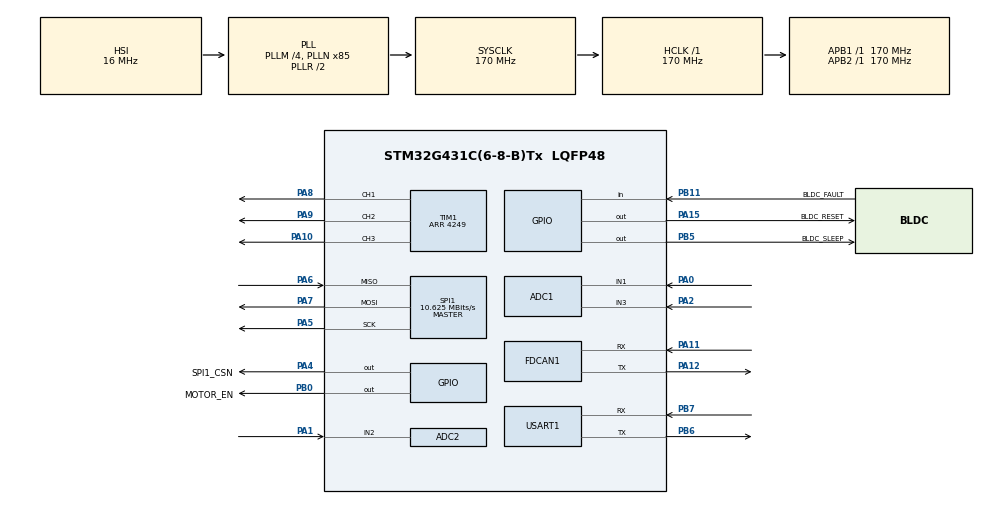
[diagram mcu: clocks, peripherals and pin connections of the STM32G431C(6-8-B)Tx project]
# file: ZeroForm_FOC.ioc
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ADC1.Channel-0\#ChannelRegularConversion=ADC_CHANNEL_3
ADC1.Channel-1\#ChannelRegularConversion=ADC_CHANNEL_TEMPSENSOR_ADC1
ADC1.ContinuousConvMode=DISABLE
ADC1.EnableInjectedConversion=ENABLE
ADC1.ExternalTrigInjecConv=ADC_EXTERNALTRIGINJEC_T1_TRGO
ADC1.InjNumberOfConversion=1
ADC1.InjectedChannel-2\#ChannelInjectedConversion=ADC_CHANNEL_1
ADC1.InjectedOffsetNumber-2\#ChannelInjectedConversion=ADC_OFFSET_NONE
ADC1.InjectedRank-2\#ChannelInjectedConversion=1
ADC1.InjectedSamplingTime-2\#ChannelInjectedConversion=ADC_SAMPLETIME_12CYCLES_5
ADC1.Mode=ADC_DUALMODE_REGSIMULT_INJECSIMULT
ADC1.NbrOfConversion=2
ADC1.NbrOfConversionFlag=1
ADC1.OffsetNumber-0\#ChannelRegularConversion=ADC_OFFSET_NONE
ADC1.OffsetNumber-1\#ChannelRegularConversion=ADC_OFFSET_NONE
ADC1.Overrun=ADC_OVR_DATA_OVERWRITTEN
ADC1.Rank-0\#ChannelRegularConversion=1
ADC1.Rank-1\#ChannelRegularConversion=2
ADC1.Rank1_Channel=ADC_CHANNEL_1
ADC1.SamplingTime-0\#ChannelRegularConversion=ADC_SAMPLETIME_640CYCLES_5
ADC1.SamplingTime-1\#ChannelRegularConversion=ADC_SAMPLETIME_640CYCLES_5
ADC1.master=1
ADC2.EnableInjectedConversion=ENABLE
ADC2.EnableRegularConversion=DISABLE
ADC2.InjNumberOfConversion=1
ADC2.InjectedChannel-1\#ChannelInjectedConversion=ADC_CHANNEL_2
ADC2.InjectedOffsetNumber-1\#ChannelInjectedConversion=ADC_OFFSET_NONE
ADC2.InjectedRank-1\#ChannelInjectedConversion=1
ADC2.InjectedSamplingTime-1\#ChannelInjectedConversion=ADC_SAMPLETIME_12CYCLES_5
ADC2.Mode=ADC_DUALMODE_REGSIMULT_INJECSIMULT
ADC2.Overrun=ADC_OVR_DATA_OVERWRITTEN
ADC2.Rank1_Channel=ADC_CHANNEL_2
FDCAN1.CalculateBaudRateNominal=999999
FDCAN1.CalculateTimeBitNominal=1000
FDCAN1.CalculateTimeQuantumNominal=29.411764705882355
FDCAN1.DataSyncJumpWidth=4
FDCAN1.DataTimeSeg1=26
FDCAN1.FrameFormat=FDCAN_FRAME_FD_BRS
FDCAN1.NominalPrescaler=5
FDCAN1.NominalSyncJumpWidth=4
FDCAN1.NominalTimeSeg1=26
FDCAN1.NominalTimeSeg2=7
Mcu.Family=STM32G4
Mcu.Name=STM32G431C(6-8-B)Tx
Mcu.Package=LQFP48
NVIC.ADC1_2_IRQn=true\:1\:0\:true\:false\:true\:true\:true\:true
NVIC.FDCAN1_IT0_IRQn=true\:0\:0\:false\:false\:true\:true\:true\:true
NVIC.PriorityGroup=NVIC_PRIORITYGROUP_4
NVIC.USART1_IRQn=true\:0\:0\:false\:false\:true\:true\:true\:true
PA0.Mode=IN1-Single-Ended
PA0.Signal=ADC1_IN1
PA1.Mode=IN2-Single-Ended
PA1.Signal=ADC2_IN2
PA10.Signal=S_TIM1_CH3
PA11.Mode=FDCAN_Activate
PA11.Signal=FDCAN1_RX
PA12.Mode=FDCAN_Activate
PA12.Signal=FDCAN1_TX
PA13.Mode=Serial_Wire
PA13.Signal=SYS_JTMS-SWDIO
PA14.Mode=Serial_Wire
PA14.Signal=SYS_JTCK-SWCLK
PA15.GPIO_Label=BLDC_RESET
PA15.Signal=GPIO_Output
PA2.Mode=IN3-Single-Ended
PA2.Signal=ADC1_IN3
PA4.GPIO_Label=SPI1_CSN
PA4.Signal=GPIO_Output
PA5.Mode=Full_Duplex_Master
PA5.Signal=SPI1_SCK
PA6.Mode=Full_Duplex_Master
PA6.Signal=SPI1_MISO
PA7.Mode=Full_Duplex_Master
PA7.Signal=SPI1_MOSI
PA8.Signal=S_TIM1_CH1
PA9.Signal=S_TIM1_CH2
PB0.GPIO_Label=MOTOR_EN
PB0.Signal=GPIO_Output
PB11.GPIO_Label=BLDC_FAULT
PB11.Signal=GPIO_Input
PB5.GPIO_Label=BLDC_SLEEP
PB5.Signal=GPIO_Output
PB6.Mode=Asynchronous
PB6.Signal=USART1_TX
PB7.Mode=Asynchronous
PB7.Signal=USART1_RX
PF0-OSC_IN.Mode=HSE-External-Oscillator
PF0-OSC_IN.Signal=RCC_OSC_IN
PF1-OSC_OUT.Mode=HSE-External-Oscillator
PF1-OSC_OUT.Signal=RCC_OSC_OUT
ProjectManager.HeapSize=0x200
ProjectManager.StackSize=0x400
ProjectManager.TargetToolchain=CMake
RCC.ADC12Freq_Value=170000000
RCC.AHBFreq_Value=170000000
RCC.APB1Freq_Value=170000000
RCC.APB1TimFreq_Value=170000000
RCC.APB2Freq_Value=170000000
RCC.APB2TimFreq_Value=170000000
RCC.CortexFreq_Value=170000000
RCC.EXTERNAL_CLOCK_VALUE=12288000
RCC.HCLKFreq_Value=170000000
RCC.HSE_VALUE=8000000
RCC.HSI48_VALUE=48000000
RCC.HSI_VALUE=16000000
RCC.LSE_VALUE=32768
RCC.PLLM=RCC_PLLM_DIV4
RCC.PLLN=85
RCC.SYSCLKFreq_VALUE=170000000
RCC.SYSCLKSource=RCC_SYSCLKSOURCE_PLLCLK
RCC.USBFreq_Value=170000000
RCC.VCOOutputFreq_Value=340000000
SH.S_TIM1_CH1.0=TIM1_CH1,PWM Generation1 CH1
SH.S_TIM1_CH2.0=TIM1_CH2,PWM Generation2 CH2
SH.S_TIM1_CH3.0=TIM1_CH3,PWM Generation3 CH3
SPI1.BaudRatePrescaler=SPI_BAUDRATEPRESCALER_16
SPI1.CLKPhase=SPI_PHASE_2EDGE
SPI1.CLKPolarity=SPI_POLARITY_HIGH
SPI1.CalculateBaudRate=10.625 MBits/s
SPI1.DataSize=SPI_DATASIZE_8BIT
SPI1.Direction=SPI_DIRECTION_2LINES
SPI1.Mode=SPI_MODE_MASTER
SPI1.VirtualType=VM_MASTER
TIM1.Channel-PWM\ Generation1\ CH1=TIM_CHANNEL_1
TIM1.Channel-PWM\ Generation2\ CH2=TIM_CHANNEL_2
TIM1.Channel-PWM\ Generation3\ CH3=TIM_CHANNEL_3
TIM1.CounterMode=TIM_COUNTERMODE_CENTERALIGNED1
TIM1.PeriodNoDither=4249
TIM1.RepetitionCounter=1
TIM1.TIM_MasterOutputTrigger=TIM_TRGO_UPDATE
USART1.VirtualMode-Asynchronous=VM_ASYNC
VP_ADC1_TempSens_Input.Mode=IN-TempSens
VP_CORDIC_VS_CORDIC.Mode=CORDIC_Activate
VP_CRC_VS_CRC.Mode=CRC_Activate
VP_SYS_VS_DBSignals.Mode=DisableDeadBatterySignals
board=custom

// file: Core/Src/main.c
/* USER CODE BEGIN Header */
/**
  ******************************************************************************
  * @file           : main.c
  * @brief          : Main program body
  ******************************************************************************
  * @attention
  *
  * Copyright (c) 2026 STMicroelectronics.
  * All rights reserved.
  *
  * This software is licensed under terms that can be found in the LICENSE file
  * in the root directory of this software component.
  * If no LICENSE file comes with this software, it is provided AS-IS.
  *
  ******************************************************************************
  */
/* USER CODE END Header */
#include "main.h"

/* USER CODE BEGIN Includes */
#include "app_main.h"
#include "stdio.h"
/* USER CODE END Includes */

ADC_HandleTypeDef hadc1;
ADC_HandleTypeDef hadc2;

CORDIC_HandleTypeDef hcordic;

CRC_HandleTypeDef hcrc;

FDCAN_HandleTypeDef hfdcan1;

SPI_HandleTypeDef hspi1;

TIM_HandleTypeDef htim1;

UART_HandleTypeDef huart1;

void SystemClock_Config(void);
static void MX_GPIO_Init(void);
static void MX_ADC1_Init(void);
static void MX_ADC2_Init(void);
static void MX_CORDIC_Init(void);
static void MX_CRC_Init(void);
static void MX_FDCAN1_Init(void);
static void MX_SPI1_Init(void);
static void MX_TIM1_Init(void);
static void MX_USART1_UART_Init(void);

int main(void)
{

  /* MCU Configuration--------------------------------------------------------*/

  /* Reset of all peripherals, Initializes the Flash interface and the Systick. */
  HAL_Init();

  /* Configure the system clock */
  SystemClock_Config();

  /* Initialize all configured peripherals */
  MX_GPIO_Init();
  MX_ADC1_Init();
  MX_ADC2_Init();
  MX_CORDIC_Init();
  MX_CRC_Init();
  MX_FDCAN1_Init();
  MX_SPI1_Init();
  MX_TIM1_Init();
  MX_USART1_UART_Init();
  /* USER CODE BEGIN 2 */
    App_Init();

  /* USER CODE END 2 */

  /* Infinite loop */
    while (1) {

    }
}

void SystemClock_Config(void)
{
  RCC_OscInitTypeDef RCC_OscInitStruct = {0};
  RCC_ClkInitTypeDef RCC_ClkInitStruct = {0};

  /** Configure the main internal regulator output voltage
  */
  HAL_PWREx_ControlVoltageScaling(PWR_REGULATOR_VOLTAGE_SCALE1_BOOST);

  /** Initializes the RCC Oscillators according to the specified parameters
  * in the RCC_OscInitTypeDef structure.
  */
  RCC_OscInitStruct.OscillatorType = RCC_OSCILLATORTYPE_HSI;
  RCC_OscInitStruct.HSIState = RCC_HSI_ON;
  RCC_OscInitStruct.HSICalibrationValue = RCC_HSICALIBRATION_DEFAULT;
  RCC_OscInitStruct.PLL.PLLState = RCC_PLL_ON;
  RCC_OscInitStruct.PLL.PLLSource = RCC_PLLSOURCE_HSI;
  RCC_OscInitStruct.PLL.PLLM = RCC_PLLM_DIV4;
  RCC_OscInitStruct.PLL.PLLN = 85;
  RCC_OscInitStruct.PLL.PLLP = RCC_PLLP_DIV2;
  RCC_OscInitStruct.PLL.PLLQ = RCC_PLLQ_DIV2;
  RCC_OscInitStruct.PLL.PLLR = RCC_PLLR_DIV2;
  if (HAL_RCC_OscConfig(&RCC_OscInitStruct) != HAL_OK)
  {
    Error_Handler();
  }

  /** Initializes the CPU, AHB and APB buses clocks
  */
  RCC_ClkInitStruct.ClockType = RCC_CLOCKTYPE_HCLK|RCC_CLOCKTYPE_SYSCLK
                              |RCC_CLOCKTYPE_PCLK1|RCC_CLOCKTYPE_PCLK2;
  RCC_ClkInitStruct.SYSCLKSource = RCC_SYSCLKSOURCE_PLLCLK;
  RCC_ClkInitStruct.AHBCLKDivider = RCC_SYSCLK_DIV1;
  RCC_ClkInitStruct.APB1CLKDivider = RCC_HCLK_DIV1;
  RCC_ClkInitStruct.APB2CLKDivider = RCC_HCLK_DIV1;

  if (HAL_RCC_ClockConfig(&RCC_ClkInitStruct, FLASH_LATENCY_4) != HAL_OK)
  {
    Error_Handler();
  }
}

static void MX_ADC1_Init(void)
{

  ADC_MultiModeTypeDef multimode = {0};
  ADC_ChannelConfTypeDef sConfig = {0};
  ADC_InjectionConfTypeDef sConfigInjected = {0};

  /** Common config
  */
  hadc1.Instance = ADC1;
  hadc1.Init.ClockPrescaler = ADC_CLOCK_SYNC_PCLK_DIV4;
  hadc1.Init.Resolution = ADC_RESOLUTION_12B;
  hadc1.Init.DataAlign = ADC_DATAALIGN_RIGHT;
  hadc1.Init.GainCompensation = 0;
  hadc1.Init.ScanConvMode = ADC_SCAN_ENABLE;
  hadc1.Init.EOCSelection = ADC_EOC_SINGLE_CONV;
  hadc1.Init.LowPowerAutoWait = DISABLE;
  hadc1.Init.ContinuousConvMode = DISABLE;
  hadc1.Init.NbrOfConversion = 2;
  hadc1.Init.DiscontinuousConvMode = DISABLE;
  hadc1.Init.ExternalTrigConv = ADC_SOFTWARE_START;
  hadc1.Init.ExternalTrigConvEdge = ADC_EXTERNALTRIGCONVEDGE_NONE;
  hadc1.Init.DMAContinuousRequests = DISABLE;
  hadc1.Init.Overrun = ADC_OVR_DATA_OVERWRITTEN;
  hadc1.Init.OversamplingMode = DISABLE;
  if (HAL_ADC_Init(&hadc1) != HAL_OK)
  {
    Error_Handler();
  }

  /** Configure the ADC multi-mode
  */
  multimode.Mode = ADC_DUALMODE_REGSIMULT_INJECSIMULT;
  multimode.DMAAccessMode = ADC_DMAACCESSMODE_DISABLED;
  multimode.TwoSamplingDelay = ADC_TWOSAMPLINGDELAY_1CYCLE;
  if (HAL_ADCEx_MultiModeConfigChannel(&hadc1, &multimode) != HAL_OK)
  {
    Error_Handler();
  }

  /** Configure Regular Channel
  */
  sConfig.Channel = ADC_CHANNEL_3;
  sConfig.Rank = ADC_REGULAR_RANK_1;
  sConfig.SamplingTime = ADC_SAMPLETIME_640CYCLES_5;
  sConfig.SingleDiff = ADC_SINGLE_ENDED;
  sConfig.OffsetNumber = ADC_OFFSET_NONE;
  sConfig.Offset = 0;
  if (HAL_ADC_ConfigChannel(&hadc1, &sConfig) != HAL_OK)
  {
    Error_Handler();
  }

  /** Configure Regular Channel
  */
  sConfig.Channel = ADC_CHANNEL_TEMPSENSOR_ADC1;
  sConfig.Rank = ADC_REGULAR_RANK_2;
  if (HAL_ADC_ConfigChannel(&hadc1, &sConfig) != HAL_OK)
  {
    Error_Handler();
  }

  /** Configure Injected Channel
  */
  sConfigInjected.InjectedChannel = ADC_CHANNEL_1;
  sConfigInjected.InjectedRank = ADC_INJECTED_RANK_1;
  sConfigInjected.InjectedSamplingTime = ADC_SAMPLETIME_12CYCLES_5;
  sConfigInjected.InjectedSingleDiff = ADC_SINGLE_ENDED;
  sConfigInjected.InjectedOffsetNumber = ADC_OFFSET_NONE;
  sConfigInjected.InjectedOffset = 0;
  sConfigInjected.InjectedNbrOfConversion = 1;
  sConfigInjected.InjectedDiscontinuousConvMode = DISABLE;
  sConfigInjected.AutoInjectedConv = DISABLE;
  sConfigInjected.QueueInjectedContext = DISABLE;
  sConfigInjected.ExternalTrigInjecConv = ADC_EXTERNALTRIGINJEC_T1_TRGO;
  sConfigInjected.ExternalTrigInjecConvEdge = ADC_EXTERNALTRIGINJECCONV_EDGE_RISING;
  sConfigInjected.InjecOversamplingMode = DISABLE;
  if (HAL_ADCEx_InjectedConfigChannel(&hadc1, &sConfigInjected) != HAL_OK)
  {
    Error_Handler();
  }

}

static void MX_ADC2_Init(void)
{

  ADC_InjectionConfTypeDef sConfigInjected = {0};

  /** Common config
  */
  hadc2.Instance = ADC2;
  hadc2.Init.ClockPrescaler = ADC_CLOCK_SYNC_PCLK_DIV4;
  hadc2.Init.Resolution = ADC_RESOLUTION_12B;
  hadc2.Init.DataAlign = ADC_DATAALIGN_RIGHT;
  hadc2.Init.GainCompensation = 0;
  hadc2.Init.ScanConvMode = ADC_SCAN_DISABLE;
  hadc2.Init.EOCSelection = ADC_EOC_SINGLE_CONV;
  hadc2.Init.LowPowerAutoWait = DISABLE;
  hadc2.Init.ContinuousConvMode = DISABLE;
  hadc2.Init.NbrOfConversion = 1;
  hadc2.Init.DiscontinuousConvMode = DISABLE;
  hadc2.Init.DMAContinuousRequests = DISABLE;
  hadc2.Init.Overrun = ADC_OVR_DATA_OVERWRITTEN;
  hadc2.Init.OversamplingMode = DISABLE;
  if (HAL_ADC_Init(&hadc2) != HAL_OK)
  {
    Error_Handler();
  }

  /** Configure Injected Channel
  */
  sConfigInjected.InjectedChannel = ADC_CHANNEL_2;
  sConfigInjected.InjectedRank = ADC_INJECTED_RANK_1;
  sConfigInjected.InjectedSamplingTime = ADC_SAMPLETIME_12CYCLES_5;
  sConfigInjected.InjectedSingleDiff = ADC_SINGLE_ENDED;
  sConfigInjected.InjectedOffsetNumber = ADC_OFFSET_NONE;
  sConfigInjected.InjectedOffset = 0;
  sConfigInjected.InjectedNbrOfConversion = 1;
  sConfigInjected.InjectedDiscontinuousConvMode = DISABLE;
  sConfigInjected.AutoInjectedConv = DISABLE;
  sConfigInjected.QueueInjectedContext = DISABLE;
  sConfigInjected.InjecOversamplingMode = DISABLE;
  if (HAL_ADCEx_InjectedConfigChannel(&hadc2, &sConfigInjected) != HAL_OK)
  {
    Error_Handler();
  }

}

static void MX_CORDIC_Init(void)
{

  hcordic.Instance = CORDIC;
  if (HAL_CORDIC_Init(&hcordic) != HAL_OK)
  {
    Error_Handler();
  }

}

static void MX_CRC_Init(void)
{

  hcrc.Instance = CRC;
  hcrc.Init.DefaultPolynomialUse = DEFAULT_POLYNOMIAL_ENABLE;
  hcrc.Init.DefaultInitValueUse = DEFAULT_INIT_VALUE_ENABLE;
  hcrc.Init.InputDataInversionMode = CRC_INPUTDATA_INVERSION_NONE;
  hcrc.Init.OutputDataInversionMode = CRC_OUTPUTDATA_INVERSION_DISABLE;
  hcrc.InputDataFormat = CRC_INPUTDATA_FORMAT_BYTES;
  if (HAL_CRC_Init(&hcrc) != HAL_OK)
  {
    Error_Handler();
  }

}

static void MX_FDCAN1_Init(void)
{

  hfdcan1.Instance = FDCAN1;
  hfdcan1.Init.ClockDivider = FDCAN_CLOCK_DIV1;
  hfdcan1.Init.FrameFormat = FDCAN_FRAME_FD_BRS;
  hfdcan1.Init.Mode = FDCAN_MODE_NORMAL;
  hfdcan1.Init.AutoRetransmission = DISABLE;
  hfdcan1.Init.TransmitPause = DISABLE;
  hfdcan1.Init.ProtocolException = DISABLE;
  hfdcan1.Init.NominalPrescaler = 5;
  hfdcan1.Init.NominalSyncJumpWidth = 4;
  hfdcan1.Init.NominalTimeSeg1 = 26;
  hfdcan1.Init.NominalTimeSeg2 = 7;
  hfdcan1.Init.DataPrescaler = 1;
  hfdcan1.Init.DataSyncJumpWidth = 4;
  hfdcan1.Init.DataTimeSeg1 = 26;
  hfdcan1.Init.DataTimeSeg2 = 1;
  hfdcan1.Init.StdFiltersNbr = 0;
  hfdcan1.Init.ExtFiltersNbr = 0;
  hfdcan1.Init.TxFifoQueueMode = FDCAN_TX_FIFO_OPERATION;
  if (HAL_FDCAN_Init(&hfdcan1) != HAL_OK)
  {
    Error_Handler();
  }

}

static void MX_SPI1_Init(void)
{

  /* SPI1 parameter configuration*/
  hspi1.Instance = SPI1;
  hspi1.Init.Mode = SPI_MODE_MASTER;
  hspi1.Init.Direction = SPI_DIRECTION_2LINES;
  hspi1.Init.DataSize = SPI_DATASIZE_8BIT;
  hspi1.Init.CLKPolarity = SPI_POLARITY_HIGH;
  hspi1.Init.CLKPhase = SPI_PHASE_2EDGE;
  hspi1.Init.NSS = SPI_NSS_SOFT;
  hspi1.Init.BaudRatePrescaler = SPI_BAUDRATEPRESCALER_16;
  hspi1.Init.FirstBit = SPI_FIRSTBIT_MSB;
  hspi1.Init.TIMode = SPI_TIMODE_DISABLE;
  hspi1.Init.CRCCalculation = SPI_CRCCALCULATION_DISABLE;
  hspi1.Init.CRCPolynomial = 7;
  hspi1.Init.CRCLength = SPI_CRC_LENGTH_DATASIZE;
  hspi1.Init.NSSPMode = SPI_NSS_PULSE_DISABLE;
  if (HAL_SPI_Init(&hspi1) != HAL_OK)
  {
    Error_Handler();
  }

}

static void MX_TIM1_Init(void)
{

  TIM_MasterConfigTypeDef sMasterConfig = {0};
  TIM_OC_InitTypeDef sConfigOC = {0};
  TIM_BreakDeadTimeConfigTypeDef sBreakDeadTimeConfig = {0};

  htim1.Instance = TIM1;
  htim1.Init.Prescaler = 0;
  htim1.Init.CounterMode = TIM_COUNTERMODE_CENTERALIGNED1;
  htim1.Init.Period = 4249;
  htim1.Init.ClockDivision = TIM_CLOCKDIVISION_DIV1;
  htim1.Init.RepetitionCounter = 1;
  htim1.Init.AutoReloadPreload = TIM_AUTORELOAD_PRELOAD_DISABLE;
  if (HAL_TIM_PWM_Init(&htim1) != HAL_OK)
  {
    Error_Handler();
  }
  sMasterConfig.MasterOutputTrigger = TIM_TRGO_UPDATE;
  sMasterConfig.MasterOutputTrigger2 = TIM_TRGO2_RESET;
  sMasterConfig.MasterSlaveMode = TIM_MASTERSLAVEMODE_DISABLE;
  if (HAL_TIMEx_MasterConfigSynchronization(&htim1, &sMasterConfig) != HAL_OK)
  {
    Error_Handler();
  }
  sConfigOC.OCMode = TIM_OCMODE_PWM1;
  sConfigOC.Pulse = 0;
  sConfigOC.OCPolarity = TIM_OCPOLARITY_HIGH;
  sConfigOC.OCNPolarity = TIM_OCNPOLARITY_HIGH;
  sConfigOC.OCFastMode = TIM_OCFAST_DISABLE;
  sConfigOC.OCIdleState = TIM_OCIDLESTATE_RESET;
  sConfigOC.OCNIdleState = TIM_OCNIDLESTATE_RESET;
  if (HAL_TIM_PWM_ConfigChannel(&htim1, &sConfigOC, TIM_CHANNEL_1) != HAL_OK)
  {
    Error_Handler();
  }
  if (HAL_TIM_PWM_ConfigChannel(&htim1, &sConfigOC, TIM_CHANNEL_2) != HAL_OK)
  {
    Error_Handler();
  }
  if (HAL_TIM_PWM_ConfigChannel(&htim1, &sConfigOC, TIM_CHANNEL_3) != HAL_OK)
  {
    Error_Handler();
  }
  sBreakDeadTimeConfig.OffStateRunMode = TIM_OSSR_DISABLE;
  sBreakDeadTimeConfig.OffStateIDLEMode = TIM_OSSI_DISABLE;
  sBreakDeadTimeConfig.LockLevel = TIM_LOCKLEVEL_OFF;
  sBreakDeadTimeConfig.DeadTime = 0;
  sBreakDeadTimeConfig.BreakState = TIM_BREAK_DISABLE;
  sBreakDeadTimeConfig.BreakPolarity = TIM_BREAKPOLARITY_HIGH;
  sBreakDeadTimeConfig.BreakFilter = 0;
  sBreakDeadTimeConfig.BreakAFMode = TIM_BREAK_AFMODE_INPUT;
  sBreakDeadTimeConfig.Break2State = TIM_BREAK2_DISABLE;
  sBreakDeadTimeConfig.Break2Polarity = TIM_BREAK2POLARITY_HIGH;
  sBreakDeadTimeConfig.Break2Filter = 0;
  sBreakDeadTimeConfig.Break2AFMode = TIM_BREAK_AFMODE_INPUT;
  sBreakDeadTimeConfig.AutomaticOutput = TIM_AUTOMATICOUTPUT_DISABLE;
  if (HAL_TIMEx_ConfigBreakDeadTime(&htim1, &sBreakDeadTimeConfig) != HAL_OK)
  {
    Error_Handler();
  }
  HAL_TIM_MspPostInit(&htim1);

}

static void MX_USART1_UART_Init(void)
{

  huart1.Instance = USART1;
  huart1.Init.BaudRate = 115200;
  huart1.Init.WordLength = UART_WORDLENGTH_8B;
  huart1.Init.StopBits = UART_STOPBITS_1;
  huart1.Init.Parity = UART_PARITY_NONE;
  huart1.Init.Mode = UART_MODE_TX_RX;
  huart1.Init.HwFlowCtl = UART_HWCONTROL_NONE;
  huart1.Init.OverSampling = UART_OVERSAMPLING_16;
  huart1.Init.OneBitSampling = UART_ONE_BIT_SAMPLE_DISABLE;
  huart1.Init.ClockPrescaler = UART_PRESCALER_DIV1;
  huart1.AdvancedInit.AdvFeatureInit = UART_ADVFEATURE_NO_INIT;
  if (HAL_UART_Init(&huart1) != HAL_OK)
  {
    Error_Handler();
  }
  if (HAL_UARTEx_SetTxFifoThreshold(&huart1, UART_TXFIFO_THRESHOLD_1_8) != HAL_OK)
  {
    Error_Handler();
  }
  if (HAL_UARTEx_SetRxFifoThreshold(&huart1, UART_RXFIFO_THRESHOLD_1_8) != HAL_OK)
  {
    Error_Handler();
  }
  if (HAL_UARTEx_DisableFifoMode(&huart1) != HAL_OK)
  {
    Error_Handler();
  }

}

static void MX_GPIO_Init(void)
{
  GPIO_InitTypeDef GPIO_InitStruct = {0};

  /* GPIO Ports Clock Enable */
  __HAL_RCC_GPIOF_CLK_ENABLE();
  __HAL_RCC_GPIOA_CLK_ENABLE();
  __HAL_RCC_GPIOB_CLK_ENABLE();

  /*Configure GPIO pin Output Level */
  HAL_GPIO_WritePin(GPIOA, SPI1_CSN_Pin|BLDC_RESET_Pin, GPIO_PIN_RESET);

  /*Configure GPIO pin Output Level */
  HAL_GPIO_WritePin(GPIOB, MOTOR_EN_Pin|BLDC_SLEEP_Pin, GPIO_PIN_RESET);

  /*Configure GPIO pins : SPI1_CSN_Pin BLDC_RESET_Pin */
  GPIO_InitStruct.Pin = SPI1_CSN_Pin|BLDC_RESET_Pin;
  GPIO_InitStruct.Mode = GPIO_MODE_OUTPUT_PP;
  GPIO_InitStruct.Pull = GPIO_NOPULL;
  GPIO_InitStruct.Speed = GPIO_SPEED_FREQ_LOW;
  HAL_GPIO_Init(GPIOA, &GPIO_InitStruct);

  /*Configure GPIO pins : MOTOR_EN_Pin BLDC_SLEEP_Pin */
  GPIO_InitStruct.Pin = MOTOR_EN_Pin|BLDC_SLEEP_Pin;
  GPIO_InitStruct.Mode = GPIO_MODE_OUTPUT_PP;
  GPIO_InitStruct.Pull = GPIO_NOPULL;
  GPIO_InitStruct.Speed = GPIO_SPEED_FREQ_LOW;
  HAL_GPIO_Init(GPIOB, &GPIO_InitStruct);

  /*Configure GPIO pin : BLDC_FAULT_Pin */
  GPIO_InitStruct.Pin = BLDC_FAULT_Pin;
  GPIO_InitStruct.Mode = GPIO_MODE_INPUT;
  GPIO_InitStruct.Pull = GPIO_NOPULL;
  HAL_GPIO_Init(BLDC_FAULT_GPIO_Port, &GPIO_InitStruct);

}

void Error_Handler(void)
{
  /* USER CODE BEGIN Error_Handler_Debug */
    HAL_TIM_PWM_Stop(&htim1, TIM_CHANNEL_1);
    HAL_TIM_PWM_Stop(&htim1, TIM_CHANNEL_2);
    HAL_TIM_PWM_Stop(&htim1, TIM_CHANNEL_3);
    printf("ERROR,FailSafe Mode \r\n");
    HAL_GPIO_WritePin(MOTOR_EN_GPIO_Port, MOTOR_EN_Pin, GPIO_PIN_RESET);
    HAL_GPIO_WritePin(BLDC_RESET_GPIO_Port, BLDC_RESET_Pin, GPIO_PIN_RESET);
    /* User can add his own implementation to report the HAL error return state */
    __disable_irq();
    while (1) {
    }
  /* USER CODE END Error_Handler_Debug */
}
